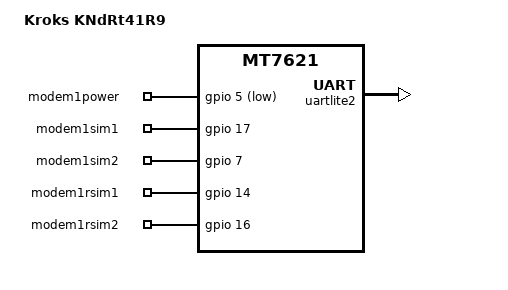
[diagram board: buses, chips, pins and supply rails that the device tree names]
#include "mt7621_kroks_wifi_mt7915.dtsi"

/ {
	compatible = "kroks,kndrt41r9", "mediatek,mt7621-soc";
	model = "Kroks KNdRt41R9";

	aliases {
		serial1 = &uartlite2;
	};

	gpio_export {
		compatible = "gpio-export";
		#size-cells = <0>;

		modem1power {
			gpio-export,name = "modem1power";
			gpio-export,output = <0>;
			gpios = <&gpio 5 GPIO_ACTIVE_LOW>;
		};

		modem1sim1 {
			gpio-export,name = "modem1sim1";
			gpio-export,output = <0>;
			gpios = <&gpio 17 GPIO_ACTIVE_HIGH>;
		};

		modem1sim2 {
			gpio-export,name = "modem1sim2";
			gpio-export,output = <0>;
			gpios = <&gpio 7 GPIO_ACTIVE_HIGH>;
		};

		modem1rsim1 {
			gpio-export,name = "modem1rsim1";
			gpio-export,output = <1>;
			gpios = <&gpio 14 GPIO_ACTIVE_HIGH>;
		};

		modem1rsim2 {
			gpio-export,name = "modem1rsim2";
			gpio-export,output = <0>;
			gpios = <&gpio 16 GPIO_ACTIVE_HIGH>;
		};
	};
};

&uartlite2 {
	status = "okay";
};

&switch0 {
	ports {
		port@3 {
			status = "okay";
			label = "lan2";
		};

		port@4 {
			status = "okay";
			label = "lan1";
		};
	};
};

&xhci {
	mediatek,u2p-dis-msk = <0x2>;
};

&pcie2 {
	status = "disabled";
};

&pcie2_phy {
	status = "disabled";
};
